# A31G34x register map
Vendor: VENDOR ABOV Semiconductor Co., Ltd.; Series: A31G34x; File version: 1.0
CPU: CM0+ r0p1, little endian, no MPU, no FPU, VTOR, 2 interrupt priority bits
Registers are 32-bit, read-only, no defined reset value unless marked. A register's access mark holds for its fields unless they carry their own. Offsets are from the block's base; [hi:lo] are bit positions.

## SPIn
Base 0x5B000000
Same registers: SPI0 0x40005800, SPI1 0x40005880
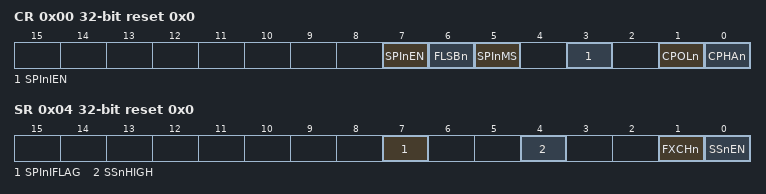
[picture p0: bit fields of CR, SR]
0x00 CR rw reset 0x0 — SPIn Control Register
  [7] SPInEN — SPIn Operation Control
    0=Disable SPIn operation; 1=Enable SPIn operation
  [6] FLSBn — Data Transmission Sequence Selection
    0=msbFirst; 1=lsbFirst
  [5] SPInMS — Master/Slave Selection
    0=Slave mode; 1=Master mode
  [3] SPInIEN — SPIn Interrupt Enable
    0=Disable SPIn interrupt; 1=Enable SPIn interrupt
  [1] CPOLn — Selects the clock polarity of SCK
    0=IdleLow (SCK to 0 when idle); 1=IdleHigh (SCK to 1 when idle)
  [0] CPHAn — The CPOLn and this bit determine if data are sampled on the leading or trailing edge of SCK
    0=StartIdle (Start with idle state.); 1=StartInverted (Start with inverted idle state.)
0x04 SR rw reset 0x0 — SPIn Status Register
  [7] SPInIFLAG — SPIn Interrupt Flag
    0=No request occurred; 1=Request occurred
  [4] SSnHIGH — This bit is set when the SSn pin goes high level during the pin is the corresponding function
    0=NoEffect; 1=High (The SSn pin has gone from low level to high)
  [1] FXCHn — SPIn Pin Function Exchange Control
    0=NoEffect; 1=Exchange MOSIn and MISOn function
  [0] SSnEN — SSn Pin Operation Control
    0=Disable SSn pin operation; 1=Enable SSn pin operation
0x08 RDR reset 0x0 — SPIn Receive Data Register
  [7:0] RDATA — SPIn Receive Data
0x0C TDR rw reset 0x0 — SPIn Transmit Data Register
  [7:0] TDATA — SPIn Transmit Data
0x10 PREDR rw reset 0x3FF — SPIn Prescaler Data Register
  [9:0] PRED — The value in this register is used to generate an SCK clock

## I2Cn
Base 0x5C000000
Same registers: I2C0 0x40004800, I2C1 0x40004900, I2C2 0x40004A00
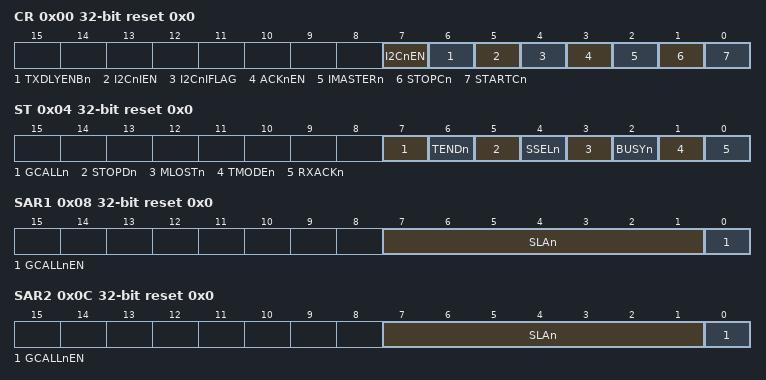
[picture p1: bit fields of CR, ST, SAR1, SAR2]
0x00 CR rw reset 0x0 — I2Cn Control Register
  [7] I2CnEN — Activate I2Cn Block by supplying
    0=Disable I2Cn block; 1=Enable I2Cn block
  [6] TXDLYENBn — I2CnSDHR Register Control
    0=Enable I2Cn_SDHR register; 1=Disable I2Cn_SDHR register
  [5] I2CnIEN — I2Cn Interrupt Enable
    0=Disable I2Cn interrupt; 1=Enable I2Cn interrupt
  [4] I2CnIFLAG — I2Cn Interrupt Flag
    0=No request occurred; 1=Request occurred
  [3] ACKnEN — Controls ACK signal generation at ninth SCL period
    0=NAK (No ACK signal is generated. (SDA = 1)); 1=ACK (ACK signal is generated. (SDA = 0))
  [2] IMASTERn ro — Represent Operation Mode of I2Cn
    0=Slave (I2Cn is in slave mode.); 1=Master (I2Cn is in master mode.)
  [1] STOPCn — STOP Condition Generation When I2Cn is master
    0=NoEffect; 1=Generate (STOP condition is to be generated.)
  [0] STARTCn — START Condition Generation When I2Cn is master
    0=NoEffect; 1=Generate (START or Repeated START condition is to be generated.)
0x04 ST rw reset 0x0 — I2Cn Status Register
  [7] GCALLn — This bit has different meaning depending on whether I2C is master or slave
    0=NoAACK_NotGCALL (No AACK is received (Master mode). General call address is not detected (Slave mode)); 1=AACK_GCALL (AACK is received (Master mode). General call address is detected (Slave mode).)
  [6] TENDn — This bit is set when 1-byte of data is transferred completely
  [5] STOPDn — This bit is set when a STOP condition is detected
  [4] SSELn — This bit is set when I2C is addressed by other master
  [3] MLOSTn — This bit represents the result of bus arbitration in master mode
  [2] BUSYn — This bit reflects bus status
  [1] TMODEn ro — This bit is used to indicate whether I2C is transmitter or receiver
  [0] RXACKn — This bit shows the state of ACK signal
0x08 SAR1 rw reset 0x0 — I2Cn Slave Address Register 1
  [7:1] SLAn — These bits configure the slave address 0 in slave mode
  [0] GCALLnEN — This bit decides whether I2Cn allows general call address 0 or not in I2Cn slave mode
0x0C SAR2 rw reset 0x0 — I2Cn Slave Address Register 2
  [7:1] SLAn — These bits configure the slave address 1 in slave mode
  [0] GCALLnEN — This bit decides whether I2Cn allows general call address 1 or not in I2Cn slave mode
0x10 DR rw reset 0x0 — I2Cn Data Register
  [7:0] DATA — The I2CnDR Transmit buffer and Receive buffer share the same I/O address with this DATA register
0x14 SDHR rw reset 0x1 — I2Cn SDA Hold Time Register
  [11:0] HLDT — This register is used to control SDA output timing from the falling edge of SCL
0x18 SCLR rw reset 0x3F — I2Cn SCL Low Period Register
  [11:0] SCLL — This register defines the low period of SCL in master mode
0x1C SCHR rw reset 0x3F — I2Cn SCL High Period Register
  [11:0] SCLH — This register defines the high period of SCL in master mode
